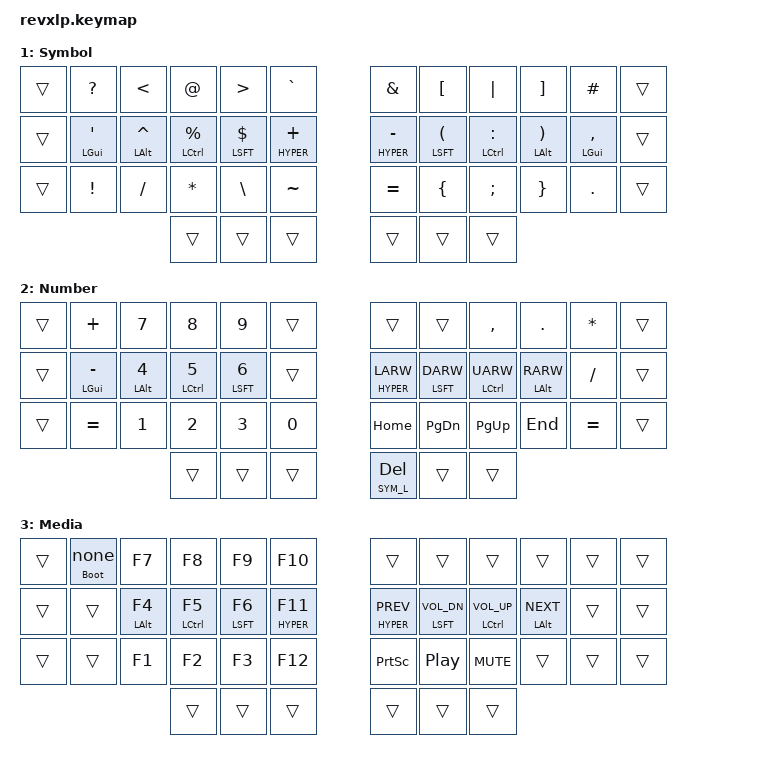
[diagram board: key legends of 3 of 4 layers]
/*
 * Copyright (c) 2020 The ZMK Contributors
 *
 * SPDX-License-Identifier: MIT
 */

#include <behaviors.dtsi>
#include <dt-bindings/zmk/keys.h>
#include <dt-bindings/zmk/bt.h>
#include <dt-bindings/zmk/backlight.h>

#define SYM_L 1
#define NUM_L 2
#define MED_L 3

/ {
    tap_dances {
        dtd: double_tap_dance {
            compatible = "zmk,behavior-tap-dance";
            label = "DOUBLE_TAP_DANCE";
            #binding-cells = <2>;
            tapping-term-ms = <200>;
            bindings = <&kp>, <&kp>;
        };
    };

    behaviors {
        // REF: https://github.com/folke/zmk-config/blob/main/config/includes/mods.dtsi
        hml: homerow_mods_left {
            compatible = "zmk,behavior-hold-tap";
            label = "HOMEROW_MODS_LEFT";
            #binding-cells = <2>;
            bindings = <&kp>, <&kp>;

            // flavor = "tap-unless-interrupted";
            flavor = "balanced";
            // tapping-term-ms = <100>;
            tapping-term-ms = <280>;
            // quick-tap-ms = <200>;
            quick-tap-ms = <175>;        // repeat on tap-into-hold
            hold-trigger-key-positions = <6 7 8 9 10 11>;
            hold-trigger-on-release;       // requires PR #1423
            // global-quick-tap-ms = <150>;         // requires PR #1387
            // global-quick-tap;
        };

        hmr: homerow_mods_right {
            compatible = "zmk,behavior-hold-tap";
            label = "HOMEROW_MODS_RIGHT";
            #binding-cells = <2>;
            bindings = <&kp>, <&kp>;

            // flavor = "tap-unless-interrupted";
            flavor = "balanced";
            // tapping-term-ms = <100>;
            tapping-term-ms = <280>;
            // quick-tap-ms = <200>;
            quick-tap-ms = <175>;        // repeat on tap-into-hold
            hold-trigger-key-positions = <0 1 2 3 4 5>;
            hold-trigger-on-release;       // requires PR #1423
            // global-quick-tap-ms = <150>;         // requires PR #1387
            // global-quick-tap;
        };

        blp: bootloader_long_press {
            compatible = "zmk,behavior-hold-tap";
            label = "BOOTLOADER_LONG_PRESS";
            #binding-cells = <2>;
            bindings = <&bootloader>, <&none>;
            tapping-term-ms = <3000>;
        };
    };

    cond_layers {
        compatible = "zmk,conditional-layers";
        tri {
          if-layers = <NUM_L SYM_L>;
          then-layer = <MED_L>;
        };
    };

    combos {
        compatible = "zmk,combos";
        bootloader_combo {
            timeout-ms = <50>;
            key-positions = <5 6>;
            bindings = <&bootloader>;
            layers = <MED_L>;
        };
    };

    keymap {
        compatible = "zmk,keymap";

        qwerty_layer {
            label = "Qwerty";
            bindings = <
&none      &dtd Q ESC      &kp W               &dtd E K_FIND       &kp R              &kp T            &dtd Y K_REDO   &kp U             &kp I           &kp O             &kp P            &none
&none      &hml LGUI A     &hml LALT S         &hml LCTL D         &hml LSFT F        &hml HYPER G     &hmr HYPER H    &hmr LSFT J       &hmr LCTL K     &hmr LALT         &hmr LGUI SEMI   &none
&none      &dtd Z K_UNDO   &dtd X K_CUT        &dtd C K_COPY       &dtd V K_PASTE     &kp B            &kp N           &kp M             &kp COMMA       &kp DOT           &kp SLASH        &none
                                               &lt SYM_L ESC       &lt NUM_L TAB      &kp SPACE        &kp BSPC        &kp SYM_L RET     &lt NUM_L DEL
            >;
        };

        sym_layer {
            label = "Symbol";
            bindings = <
&trans     &kp QUESTION    &kp LESS_THAN       &kp AT             &kp GREATER_THAN    &kp GRAVE       &kp AMPERSAND    &kp LEFT_BRACKET  &kp PIPE        &kp RIGHT_BRACKET &kp HASH        &trans
&trans     &hml LGUI SQT   &hml LALT CARET     &hml LCTL PERCENT  &hml LSFT DOLLAR    &hml HYPER PLUS &hmr HYPER MINUS &hmr LSFT LPAR    &hmr LCTL COLON &hmr LALT RPAR    &hmr LGUI COMMA &trans
&trans     &kp EXCLAMATION &kp SLASH           &kp ASTERISK       &kp BACKSLASH       &kp TILDE       &kp EQUAL        &kp LBRC          &kp SEMICOLON   &kp RBRC          &kp DOT         &trans
                                               &trans             &trans              &trans          &trans           &trans            &trans
            >;
        };

        num_layer {
            label = "Number";
            bindings = <
&trans     &kp PLUS        &kp N7             &kp N8             &kp N9              &trans          &trans           &trans            &kp COMMA        &kp DOT          &kp ASTERISK     &trans
&trans     &hmr LGUI MINUS &hmr LALT N4       &hmr LCTL N5       &hmr LSFT N6        &trans          &hmr HYPER LARW  &hmr LSFT DARW    &hmr LCTL UARW   &hmr LALT RARW   &kp SLASH        &trans
&trans     &kp EQUAL       &kp N1             &kp N2             &kp N3              &kp N0          &kp HOME         &kp PG_DN         &kp PG_UP        &kp END          &kp EQUAL        &trans
                                              &trans             &trans              &trans          &lt SYM_L DEL    &trans            &trans
            >;
        };

        media_layer {
            label = "Media";
            bindings = <
&trans     &blp 0 0       &trans              &trans              &trans             &trans            &trans         &kp F7            &kp F8           &kp F9           &kp F10          &trans
&trans     &trans         &hml LALT C_PREV    &hml LCTL C_VOL_DN  &hml LSFT C_VOL_UP &hml HYPER C_NEXT &trans         &hmr LSFT F4      &hmr LCTL F5     &hmr LALT F6     &hmr LGUI F11    &trans
&trans     &trans         &kp C_PLAY_PAUSE    &kp C_MUTE          &trans             &trans            &trans         &kp F1            &kp F2           &kp F3           &kp F12          &trans
                                              &trans              &trans             &trans            &trans         &trans            &trans
            >;
        };

        media_layer {
            label = "Media";
            bindings = <
&trans     &blp 0 0       &kp F7              &kp F8              &kp F9             &kp F10           &trans         &trans            &trans           &trans           &trans            &trans
&trans     &trans         &hml LALT F4        &hml LCTL F5        &hml LSFT F6       &hml HYPER F11    &hmr HYPER C_PREV &hmr LSFT C_VOL_DN &hmr LCTL C_VOL_UP &hmr LALT C_NEXT &trans      &trans
&trans     &trans         &kp F1              &kp F2              &kp F3             &kp F12           &kp PSCRN      &kp C_PLAY_PAUSE  &kp C_MUTE       &trans           &trans            &trans
                                              &trans              &trans             &trans            &trans         &trans            &trans
            >;
        };
    };
};
